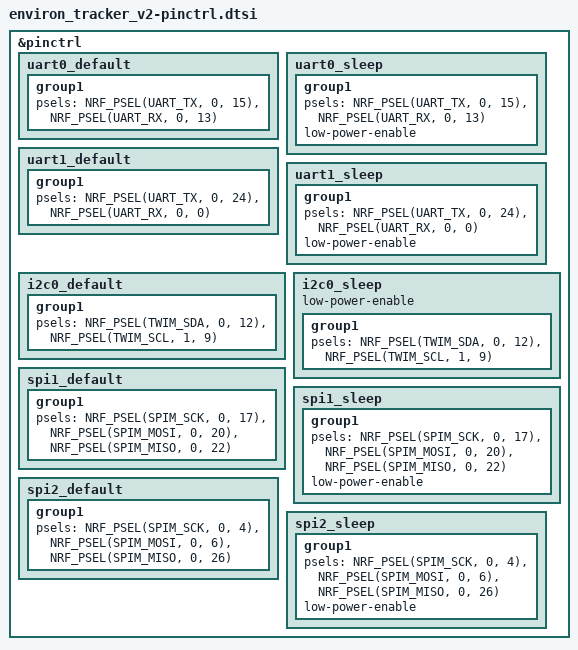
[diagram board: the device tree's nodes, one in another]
&pinctrl {
    uart0_default: uart0_default {
        group1 {
            psels = <NRF_PSEL(UART_TX, 0, 15)>,
                    <NRF_PSEL(UART_RX, 0, 13)>;
        };
    };

    uart0_sleep: uart0_sleep {
        group1 {
            psels = <NRF_PSEL(UART_TX, 0, 15)>,
                    <NRF_PSEL(UART_RX, 0, 13)>;
            low-power-enable;
        };
    };

    uart1_default: uart1_default {
        group1 {
            psels = <NRF_PSEL(UART_TX, 0, 24)>,
                    <NRF_PSEL(UART_RX, 0, 0)>;
        };
    };

    uart1_sleep: uart1_sleep {
        group1 {
            psels = <NRF_PSEL(UART_TX, 0, 24)>,
                    <NRF_PSEL(UART_RX, 0, 0)>;
            low-power-enable;
        };
    };

    i2c0_default: i2c0_default {
        group1 {
            psels = <NRF_PSEL(TWIM_SDA, 0, 12)>,
                    <NRF_PSEL(TWIM_SCL, 1, 9)>;
        };
    };

    i2c0_sleep: i2c0_sleep {
        group1 {
            psels = <NRF_PSEL(TWIM_SDA, 0, 12)>,
                    <NRF_PSEL(TWIM_SCL, 1, 9)>;
        };
        low-power-enable;
    };

    spi1_default: spi1_default {
        group1 {
            psels = <NRF_PSEL(SPIM_SCK, 0, 17)>,
                    <NRF_PSEL(SPIM_MOSI, 0, 20)>,
                    <NRF_PSEL(SPIM_MISO, 0, 22)>;
        };
    };

    spi1_sleep: spi1_sleep {
        group1 {
            psels = <NRF_PSEL(SPIM_SCK, 0, 17)>,
                    <NRF_PSEL(SPIM_MOSI, 0, 20)>,
                    <NRF_PSEL(SPIM_MISO, 0, 22)>;
            low-power-enable;
        };
    };

    spi2_default: spi2_default {
        group1 {
            psels = <NRF_PSEL(SPIM_SCK, 0, 4)>,
                    <NRF_PSEL(SPIM_MOSI, 0, 6)>,
                    <NRF_PSEL(SPIM_MISO, 0, 26)>;
        };
    };

    spi2_sleep: spi2_sleep {
        group1 {
            psels = <NRF_PSEL(SPIM_SCK, 0, 4)>,
                    <NRF_PSEL(SPIM_MOSI, 0, 6)>,
                    <NRF_PSEL(SPIM_MISO, 0, 26)>;
            low-power-enable;
        };
    };
};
